AUTOSAR XML (schema 4-2-1)
package /MICROSAR/Dcm_swc
  mode declaration group DcmControlDtcSetting: initial-mode=ENABLEDTCSETTING, on-transition-value=2
    mode ENABLEDTCSETTING: value=0
    mode DISABLEDTCSETTING: value=1
  mode declaration group DcmEcuReset: initial-mode=NONE, on-transition-value=7
    7 x mode:
      NONE: value=0
      HARD: value=1
      KEYONOFF: value=2
      SOFT: value=3
      JUMPTOBOOTLOADER: value=4
      JUMPTOSYSSUPPLIERBOOTLOADER: value=5
      EXECUTE: value=6
  mode declaration group DcmDiagnosticSessionControl: initial-mode=DefaultSession, on-transition-value=255
    mode DefaultSession: value=1
    mode ProgrammingSession: value=2
    mode ExtendedSession: value=3
  data type mapping set DcmMappingSet  # Contains mapping for ModeDeclarationGroups which are provided by Dcm.
    mode-request-type-maps:
      implementation-data-type=Dcm_ControlDtcSettingType, mode-group=DcmControlDtcSetting
      implementation-data-type=Dcm_EcuResetType, mode-group=DcmEcuReset
      implementation-data-type=Dcm_DiagnosticSessionControlType, mode-group=DcmDiagnosticSessionControl
package /MICROSAR/Dcm_swc/ComponentTypes
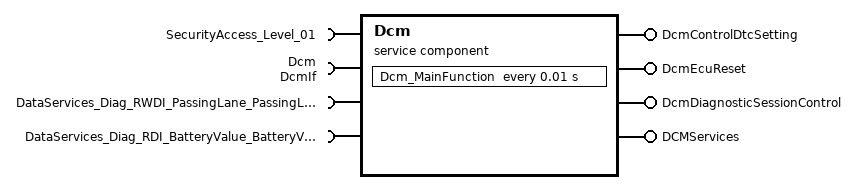
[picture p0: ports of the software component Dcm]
  service sw component type Dcm: category=SERVICE_COMPONENT
    4 x provide port:
      DcmControlDtcSetting: provided-interface=DcmControlDtcSetting
      DcmEcuReset: mode-switch-sender-com-spec{mode-group=DcmEcuReset, mode-switched-ack=timeout=0}, provided-interface=DcmEcuReset
      DcmDiagnosticSessionControl: provided-interface=DcmDiagnosticSessionControl
      DCMServices: provided-interface=DCMServices
    4 x require port:
      SecurityAccess_Level_01: required-interface=SecurityAccess_Level_01
      Dcm: required-interface=DcmIf
      DataServices_Diag_RWDI_PassingLane_PassingLane_PassingLane: required-interface=DataServices_Diag_RWDI_PassingLane_PassingLane_PassingLane
      DataServices_Diag_RDI_BatteryValue_BatteryValue: required-interface=DataServices_Diag_RDI_BatteryValue_BatteryValue
    behavior DcmInternalBehavior: handle-termination-and-restart=NO-SUPPORT, included-data-type-set=data-type=[Dcm_ConfirmationStatusType, Dcm_OpStatusType, Dcm_NegativeResponseCodeType, Dcm_ProtocolType, Dcm_SecLevelType, Dcm_SesCtrlType, Dcm_ControlDtcSettingType, Dcm_EcuResetType, Dcm_DiagnosticSessionControlType, Dcm_CommunicationModeType]
      timing event Timer_Dcm_MainFunction: start-on-event=Dcm_MainFunction, period=0.01
      5 x operation invoked event:
        OpEventGetActiveProtocol_GetActiveProtocol_DCMServices: start-on-event=GetActiveProtocol, operation=DCMServices.GetActiveProtocol
        OpEventGetSesCtrlType_GetSesCtrlType_DCMServices: start-on-event=GetSesCtrlType, operation=DCMServices.GetSesCtrlType
        OpEventResetToDefaultSession_ResetToDefaultSession_DCMServices: start-on-event=ResetToDefaultSession, operation=DCMServices.ResetToDefaultSession
        OpEventGetSecurityLevel_GetSecurityLevel_DCMServices: start-on-event=GetSecurityLevel, operation=DCMServices.GetSecurityLevel
        OpEventSetActiveDiagnostic_SetActiveDiagnostic_DCMServices: start-on-event=SetActiveDiagnostic, operation=DCMServices.SetActiveDiagnostic
      port-api-options:
        enable-take-address=true, indirect-api=false, port=DcmControlDtcSetting
        enable-take-address=true, indirect-api=false, port=DcmEcuReset
        enable-take-address=true, indirect-api=false, port=DcmDiagnosticSessionControl
        enable-take-address=true, indirect-api=false, port=DCMServices
        enable-take-address=true, indirect-api=false, port=SecurityAccess_Level_01
        enable-take-address=true, indirect-api=false, port=Dcm
        enable-take-address=true, indirect-api=false, port=DataServices_Diag_RWDI_PassingLane_PassingLane_PassingLane
        enable-take-address=true, indirect-api=false, port=DataServices_Diag_RDI_BatteryValue_BatteryValue
      6 x runnable:
        Dcm_MainFunction
          mode switch point ModeSwitchPointDcm_MainFunction_DcmControlDtcSetting_DcmControlDtcSetting: mode-group=DcmControlDtcSetting.DcmControlDtcSetting
          mode switch point ModeSwitchPointDcm_MainFunction_DcmEcuReset_DcmEcuReset: mode-group=DcmEcuReset.DcmEcuReset
          mode switch point ModeSwitchPointDcm_MainFunction_DcmDiagnosticSessionControl_DcmDiagnosticSessionControl: mode-group=DcmDiagnosticSessionControl.DcmDiagnosticSessionControl
          10 x sync call, all with timeout=0:
            OpServerCallDcm_MainFunction_GetSeed_SecurityAccess_Level_01: operation=SecurityAccess_Level_01.GetSeed
            OpServerCallDcm_MainFunction_CompareKey_SecurityAccess_Level_01: operation=SecurityAccess_Level_01.CompareKey
            OpServerCallDcm_MainFunction_DcmClearDTC_Dcm: operation=Dcm.DcmClearDTC
            OpServerCallDcm_MainFunction_DcmEnableDTCSetting_Dcm: operation=Dcm.DcmEnableDTCSetting
            OpServerCallDcm_MainFunction_DcmGetExtendedDataRecordByDTC_Dcm: operation=Dcm.DcmGetExtendedDataRecordByDTC
            OpServerCallDcm_MainFunction_ReadData_DataServices_Diag_RWDI_PassingLane_PassingLane_PassingLane: operation=DataServices_Diag_RWDI_PassingLane_PassingLane_PassingLane.ReadData
            OpServerCallDcm_MainFunction_ConditionCheckRead_DataServices_Diag_RWDI_PassingLane_PassingLane_PassingLane: operation=DataServices_Diag_RWDI_PassingLane_PassingLane_PassingLane.ConditionCheckRead
            OpServerCallDcm_MainFunction_WriteData_DataServices_Diag_RWDI_PassingLane_PassingLane_PassingLane: operation=DataServices_Diag_RWDI_PassingLane_PassingLane_PassingLane.WriteData
            OpServerCallDcm_MainFunction_ReadData_DataServices_Diag_RDI_BatteryValue_BatteryValue: operation=DataServices_Diag_RDI_BatteryValue_BatteryValue.ReadData
            OpServerCallDcm_MainFunction_ConditionCheckRead_DataServices_Diag_RDI_BatteryValue_BatteryValue: operation=DataServices_Diag_RDI_BatteryValue_BatteryValue.ConditionCheckRead
        GetActiveProtocol: can-be-invoked-concurrently=true, symbol=Dcm_GetActiveProtocol
        GetSesCtrlType: can-be-invoked-concurrently=true, symbol=Dcm_GetSesCtrlType
        ResetToDefaultSession: can-be-invoked-concurrently=true, symbol=Dcm_ResetToDefaultSession
        GetSecurityLevel: can-be-invoked-concurrently=true, symbol=Dcm_GetSecurityLevel
        SetActiveDiagnostic: can-be-invoked-concurrently=true, symbol=Dcm_SetActiveDiagnostic
  swc implementation DcmImplementation: programming-language=C, behavior=DcmInternalBehavior
package /MICROSAR/Dcm_swc/DataTypes
  17 x impl type:
    Dcm_ConfirmationStatusType: compu {0=DCM_RES_POS_OK, 1=DCM_RES_POS_NOT_OK, 2=DCM_RES_NEG_OK, 3=DCM_RES_NEG_NOT_OK}, implementation-data-type=uint8
    Dcm_OpStatusType: compu {0=DCM_INITIAL, 1=DCM_PENDING, 2=DCM_CANCEL, 3=DCM_FORCE_RCRRP_OK, 64=DCM_FORCE_RCRRP_NOT_OK}, implementation-data-type=uint8
    Dcm_NegativeResponseCodeType: compu {0=DCM_E_POSITIVERESPONSE, 16=DCM_E_GENERALREJECT, 17=DCM_E_SERVICENOTSUPPORTED, 18=DCM_E_SUBFUNCTIONNOTSUPPORTED, 19=DCM_E_INCORRECTMESSAGELENGTHORINVALIDFORMAT, 20=DCM_E_RESPONSETOOLONG, 33=DCM_E_BUSYREPEATREQUEST, 34=DCM_E_CONDITIONSNOTCORRECT, 36=DCM_E_REQUESTSEQUENCEERROR, 37=DCM_E_NORESPONSEFROMSUBNETCOMPONENT, 38=DCM_E_FAILUREPREVENTSEXECUTIONOFREQUESTEDACTION, 49=DCM_E_REQUESTOUTOFRANGE, 51=DCM_E_SECURITYACCESSDENIED, 53=DCM_E_INVALIDKEY, 54=DCM_E_EXCEEDNUMBEROFATTEMPTS, 55=DCM_E_REQUIREDTIMEDELAYNOTEXPIRED, 112=DCM_E_UPLOADDOWNLOADNOTACCEPTED, 113=DCM_E_TRANSFERDATASUSPENDED, 114=DCM_E_GENERALPROGRAMMINGFAILURE, 115=DCM_E_WRONGBLOCKSEQUENCECOUNTER, 120=DCM_E_REQUESTCORRECTLYRECEIVEDRESPONSEPENDING, 126=DCM_E_SUBFUNCTIONNOTSUPPORTEDINACTIVESESSION, 127=DCM_E_SERVICENOTSUPPORTEDINACTIVESESSION, 129=DCM_E_RPMTOOHIGH, 130=DCM_E_RPMTOOLOW, 131=DCM_E_ENGINEISRUNNING, 132=DCM_E_ENGINEISNOTRUNNING, 133=DCM_E_ENGINERUNTIMETOOLOW, 134=DCM_E_TEMPERATURETOOHIGH, 135=DCM_E_TEMPERATURETOOLOW, 136=DCM_E_VEHICLESPEEDTOOHIGH, 137=DCM_E_VEHICLESPEEDTOOLOW, 138=DCM_E_THROTTLE_PEDALTOOHIGH, 139=DCM_E_THROTTLE_PEDALTOOLOW, 140=DCM_E_TRANSMISSIONRANGENOTINNEUTRAL, 141=DCM_E_TRANSMISSIONRANGENOTINGEAR, 143=DCM_E_BRAKESWITCH_NOTCLOSED, 144=DCM_E_SHIFTERLEVERNOTINPARK, 145=DCM_E_TORQUECONVERTERCLUTCHLOCKED, 146=DCM_E_VOLTAGETOOHIGH, 147=DCM_E_VOLTAGETOOLOW, 240..249=DCM_E_VMSCNC_0..DCM_E_VMSCNC_9, 250=DCM_E_VMSCNC_A, 251=DCM_E_VMSCNC_B, 252=DCM_E_VMSCNC_C, 253=DCM_E_VMSCNC_D, 254=DCM_E_VMSCNC_E}, implementation-data-type=uint8
    Dcm_ProtocolType: compu {0=DCM_OBD_ON_CAN, 1=DCM_OBD_ON_FLEXRAY, 2=DCM_OBD_ON_IP, 3=DCM_UDS_ON_CAN, 4=DCM_UDS_ON_FLEXRAY, 5=DCM_UDS_ON_IP, 12=DCM_NO_ACTIVE_PROTOCOL, 240..254=DCM_SUPPLIER_1..DCM_SUPPLIER_15}, implementation-data-type=uint8
    Dcm_SecLevelType: compu {0=DCM_SEC_LEV_LOCKED, 1=DCM_SEC_LEV_L1}, implementation-data-type=uint8
    Dcm_SesCtrlType: compu {1=DCM_DEFAULT_SESSION, 2=DCM_PROGRAMMING_SESSION, 3=DCM_EXTENDED_DIAGNOSTIC_SESSION}, implementation-data-type=uint8
    Dem_DTCFormatType: compu {0=DEM_DTC_FORMAT_OBD, 1=DEM_DTC_FORMAT_UDS}, implementation-data-type=uint8
    Dem_DTCKindType: compu {1=DEM_DTC_KIND_ALL_DTCS, 2=DEM_DTC_KIND_EMISSION_REL_DTCS}, implementation-data-type=uint8
    Dem_DTCGroupType: range raw 0..16777215, implementation-data-type=uint32
    Dem_DTCOriginType: compu {1=DEM_DTC_ORIGIN_PRIMARY_MEMORY, 2=DEM_DTC_ORIGIN_MIRROR_MEMORY, 3=DEM_DTC_ORIGIN_PERMANENT_MEMORY, 4=DEM_DTC_ORIGIN_SECONDARY_MEMORY}, implementation-data-type=uint8
    Dcm_ControlDtcSettingType: compu {0=DCM_ENUM_ENABLEDTCSETTING, 1=DCM_ENUM_DISABLEDTCSETTING}, implementation-data-type=uint8
    Dcm_EcuResetType: compu {0=DCM_ENUM_NONE, 1=DCM_ENUM_HARD, 2=DCM_ENUM_KEYONOFF, 3=DCM_ENUM_SOFT, 4=DCM_ENUM_JUMPTOBOOTLOADER, 5=DCM_ENUM_JUMPTOSYSSUPPLIERBOOTLOADER, 6=DCM_ENUM_EXECUTE}, implementation-data-type=uint8
    Dcm_DiagnosticSessionControlType: compu {1=DCM_ENUM_DefaultSession, 2=DCM_ENUM_ProgrammingSession, 3=DCM_ENUM_ExtendedSession}, implementation-data-type=uint8
    Dcm_CommunicationModeType: compu {0=DCM_ENABLE_RX_TX_NORM, 1=DCM_ENABLE_RX_DISABLE_TX_NORM, 2=DCM_DISABLE_RX_ENABLE_TX_NORM, 3=DCM_DISABLE_RX_TX_NORMAL, 4=DCM_ENABLE_RX_TX_NM, 5=DCM_ENABLE_RX_DISABLE_TX_NM, 6=DCM_DISABLE_RX_ENABLE_TX_NM, 7=DCM_DISABLE_RX_TX_NM, 8=DCM_ENABLE_RX_TX_NORM_NM, 9=DCM_ENABLE_RX_DISABLE_TX_NORM_NM, 10=DCM_DISABLE_RX_ENABLE_TX_NORM_NM, 11=DCM_DISABLE_RX_TX_NORM_NM}, implementation-data-type=uint8
    Dcm_Data2ByteType: category=ARRAY, sw-calibration-access=READ-ONLY
      element Dcm_Data2ByteTypeElement: array-size=2, array-size-semantics=FIXED-SIZE, implementation-data-type=uint8
    Dcm_Data4ByteType: category=ARRAY, sw-calibration-access=READ-ONLY
      element Dcm_Data4ByteTypeElement: array-size=4, array-size-semantics=FIXED-SIZE, implementation-data-type=uint8
    Dcm_Data1ByteType: category=ARRAY, sw-calibration-access=READ-ONLY
      element Dcm_Data1ByteTypeElement: array-size=1, array-size-semantics=FIXED-SIZE, implementation-data-type=uint8
package /MICROSAR/Dcm_swc/Interfaces
  mode switch interface DcmControlDtcSetting: is-service=true, service-kind=DIAGNOSTIC-COMMUNICATION-MANAGER
    mode group DcmControlDtcSetting: type=DcmControlDtcSetting
  mode switch interface DcmEcuReset: is-service=true, service-kind=DIAGNOSTIC-COMMUNICATION-MANAGER
    mode group DcmEcuReset: type=DcmEcuReset
  mode switch interface DcmDiagnosticSessionControl: is-service=true, service-kind=DIAGNOSTIC-COMMUNICATION-MANAGER
    mode group DcmDiagnosticSessionControl: type=DcmDiagnosticSessionControl
  5 x client server interface, all with is-service=true, service-kind=DIAGNOSTIC-COMMUNICATION-MANAGER:
    DCMServices
      5 x operation:
        GetActiveProtocol: possible-error=DCMServices/E_NOT_OK
          arg ActiveProtocol: type=Dcm_ProtocolType, direction=OUT
        GetSesCtrlType: possible-error=DCMServices/E_NOT_OK
          arg SesCtrlType: type=Dcm_SesCtrlType, direction=OUT
        ResetToDefaultSession: possible-error=DCMServices/E_NOT_OK
        GetSecurityLevel: possible-error=DCMServices/E_NOT_OK
          arg SecLevel: type=Dcm_SecLevelType, direction=OUT
        SetActiveDiagnostic: possible-error=E_OK
          arg active: type=boolean, direction=IN
      error E_OK: error-code=0
      error E_NOT_OK: error-code=1
    SecurityAccess_Level_01
      operation GetSeed: possible-error=[SecurityAccess_Level_01/E_NOT_OK, SecurityAccess_Level_01/E_PENDING]
        arg OpStatus: type=Dcm_OpStatusType, direction=IN
        arg Seed: type=Dcm_Data2ByteType, direction=OUT
        arg ErrorCode: type=Dcm_NegativeResponseCodeType, direction=OUT
      operation CompareKey: possible-error=[SecurityAccess_Level_01/E_NOT_OK, SecurityAccess_Level_01/E_PENDING, E_COMPARE_KEY_FAILED]
        arg Key: type=Dcm_Data2ByteType, direction=IN
        arg OpStatus: type=Dcm_OpStatusType, direction=IN
      error E_NOT_OK: error-code=1
      error E_PENDING: error-code=10
      error E_COMPARE_KEY_FAILED: error-code=11
    DcmIf
      operation DcmClearDTC: possible-error=[DEM_CLEAR_WRONG_DTC, DEM_CLEAR_WRONG_DTCORIGIN, DEM_CLEAR_FAILED, DEM_CLEAR_PENDING, DEM_CLEAR_BUSY, DEM_CLEAR_MEMORY_ERROR]
        arg DTC: type=uint32, direction=IN
        arg DTCFormat: type=Dem_DTCFormatType, direction=IN
        arg DTCOrigin: type=Dem_DTCOriginType, direction=IN
      operation DcmEnableDTCSetting: possible-error=[DEM_CONTROL_DTC_SETTING_N_OK, DEM_CONTROL_DTC_WRONG_DTCGROUP]
        arg DTCGroup: type=Dem_DTCGroupType, direction=IN
        arg DTCKind: type=Dem_DTCKindType, direction=IN
      operation DcmGetExtendedDataRecordByDTC: possible-error=[DEM_RECORD_WRONG_DTC, DEM_RECORD_WRONG_DTCORIGIN, DEM_RECORD_WRONG_NUMBER, DEM_RECORD_WRONG_BUFFERSIZE, DEM_RECORD_PENDING]
        5 x arg:
          DTC: type=uint32, direction=IN
          DTCOrigin: type=Dem_DTCOriginType, direction=IN
          ExtendedDataNumber: type=uint8, direction=IN
          DestBuffer: type=uint8, direction=OUT
          BufSize: type=uint16, direction=INOUT
      13 x error:
        DEM_CLEAR_WRONG_DTC: error-code=1
        DEM_CONTROL_DTC_SETTING_N_OK: error-code=1
        DEM_CLEAR_WRONG_DTCORIGIN: error-code=2
        DEM_CONTROL_DTC_WRONG_DTCGROUP: error-code=2
        DEM_CLEAR_FAILED: error-code=3
        DEM_CLEAR_PENDING: error-code=4
        DEM_CLEAR_BUSY: error-code=5
        DEM_CLEAR_MEMORY_ERROR: error-code=6
        DEM_RECORD_WRONG_DTC: error-code=1
        DEM_RECORD_WRONG_DTCORIGIN: error-code=2
        DEM_RECORD_WRONG_NUMBER: error-code=3
        DEM_RECORD_WRONG_BUFFERSIZE: error-code=4
        DEM_RECORD_PENDING: error-code=5
    DataServices_Diag_RWDI_PassingLane_PassingLane_PassingLane
      operation ReadData: possible-error=[DataServices_Diag_RWDI_PassingLane_PassingLane_PassingLane/E_NOT_OK, DataServices_Diag_RWDI_PassingLane_PassingLane_PassingLane/E_PENDING]
        arg OpStatus: type=Dcm_OpStatusType, direction=IN
        arg Data: type=Dcm_Data1ByteType, direction=OUT
      operation ConditionCheckRead: possible-error=[DataServices_Diag_RWDI_PassingLane_PassingLane_PassingLane/E_NOT_OK, DataServices_Diag_RWDI_PassingLane_PassingLane_PassingLane/E_PENDING]
        arg OpStatus: type=Dcm_OpStatusType, direction=IN
        arg ErrorCode: type=Dcm_NegativeResponseCodeType, direction=OUT
      operation WriteData: possible-error=[DataServices_Diag_RWDI_PassingLane_PassingLane_PassingLane/E_NOT_OK, DataServices_Diag_RWDI_PassingLane_PassingLane_PassingLane/E_PENDING]
        arg Data: type=Dcm_Data1ByteType, direction=IN
        arg OpStatus: type=Dcm_OpStatusType, direction=IN
        arg ErrorCode: type=Dcm_NegativeResponseCodeType, direction=OUT
      error E_NOT_OK: error-code=1
      error E_PENDING: error-code=10
    DataServices_Diag_RDI_BatteryValue_BatteryValue
      operation ReadData: possible-error=[DataServices_Diag_RDI_BatteryValue_BatteryValue/E_NOT_OK, DataServices_Diag_RDI_BatteryValue_BatteryValue/E_PENDING]
        arg OpStatus: type=Dcm_OpStatusType, direction=IN
        arg Data: type=Dcm_Data4ByteType, direction=OUT
      operation ConditionCheckRead: possible-error=[DataServices_Diag_RDI_BatteryValue_BatteryValue/E_NOT_OK, DataServices_Diag_RDI_BatteryValue_BatteryValue/E_PENDING]
        arg OpStatus: type=Dcm_OpStatusType, direction=IN
        arg ErrorCode: type=Dcm_NegativeResponseCodeType, direction=OUT
      error E_NOT_OK: error-code=1
      error E_PENDING: error-code=10
